VERSION ""

NS_ :

BS_:

BU_: BMS MC PDM D153 VCU

BO_ 165 INV_motorPositionInfo: 8 BMS
 SG_ INV_motorSpeed : 0|16@1- (0.1,0) [0|6500] ""  D153

BO_ 167 INV_voltageInfo: 8 MC
 SG_ INV_dcBusVoltage : 7|16@0- (1,0) [0|600] ""  D153

BO_ 170 INV_internalStates: 8 MC
 SG_ INV_limitCoolantDerating : 6|1@0- (1,-1) [-1|1] ""  D153
 SG_ INV_bmsTorqueLimiting : 7|1@0- (1,-1) [-1|1] ""  D153

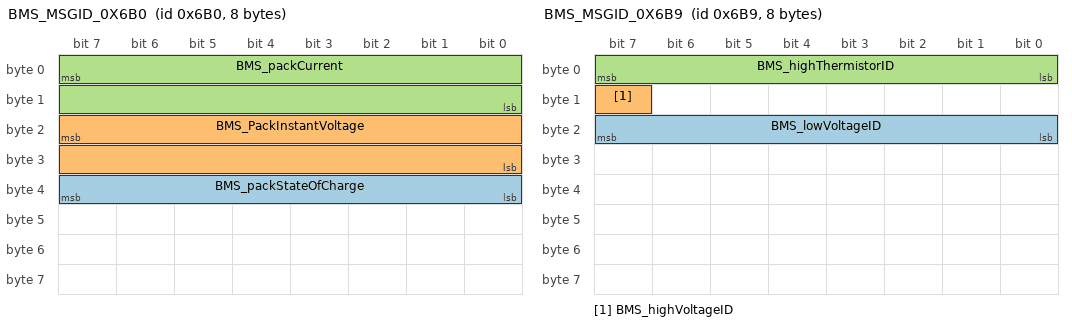
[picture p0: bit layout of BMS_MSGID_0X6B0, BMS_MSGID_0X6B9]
BO_ 1712 BMS_MSGID_0X6B0: 8 BMS
 SG_ BMS_packStateOfCharge : 39|8@0- (1,0) [0|100] ""  D153
 SG_ BMS_PackInstantVoltage : 23|16@0- (0.01,0) [0|600] "Volts"  D153
 SG_ BMS_packCurrent : 7|16@0- (0.01,0) [0|200] "Amps"  D153

BO_ 1714 BMS_MSGID_0X6B2: 8 BMS
 SG_ BMS_failsafeStatuses : 7|8@0- (1,0) [1|180] ""  D153

BO_ 54 BMS_MSGID_0X36_CELLBCAST: 8 BMS
 SG_ BMS_cellBalancing : 7|8@0- (1,0) [1|180] "bool"  D153

BO_ 1721 BMS_MSGID_0X6B9: 8 BMS
 SG_ BMS_lowVoltageID : 23|8@0- (1,0) [1|180] ""  D153
 SG_ BMS_highVoltageID : 15|1@0- (1,0) [1|180] ""  D153
 SG_ BMS_highThermistorID : 7|8@0- (1,0) [1|180] ""  D153

BO_ 1715 BMS_MSGID_0X6B3: 8 BMS
 SG_ BMS_lowThermistorID : 7|8@0- (1,0) [1|180] ""  D153

BO_ 1360 VCU_warning10Hz: 8 VCU
 SG_ VCU_mcCoolantFlowRateDiag m0 : 62|1@0- (1,0) [0|1] ""  D153
 SG_ VCU_gpsDiag m1 : 11|1@0- (1,0) [0|1] ""  D153
 SG_ VCU_CANBus3Diagnostic m1 : 13|1@0- (1,0) [0|1] ""  D153
 SG_ VCU_CANBus2Diagnostic m1 : 14|1@0- (1,0) [0|1] ""  D153
 SG_ VCU_CANBus1Diagnostic m1 : 15|1@0- (1,0) [0|1] ""  D153
 SG_ VCU_brakePressureSensorDiag m0 : 58|1@0- (1,0) [0|1] ""  D153
 SG_ VCU_warning10HzMux M : 7|8@0+ (1,0) [0|255] ""  D153
 SG_ VCU_tsOverPowerWarning m0 : 35|1@0- (1,0) [0|1] ""  D153
 SG_ VCU_throttlePedalSensorDiag m0 : 59|1@0- (1,0) [0|1] ""  D153
 SG_ VCU_rs232Diag m1 : 12|1@0- (1,0) [0|1] ""  D153
 SG_ VCU_radiatorCoolantFlowRateDiag m0 : 60|1@0- (1,0) [0|1] ""  D153
 SG_ VCU_radCoolantTempOutWarning m0 : 8|1@0- (1,0) [0|1] ""  D153
 SG_ VCU_radCoolantTempOutDiag m0 : 40|1@0- (1,0) [0|1] ""  D153
 SG_ VCU_radCoolantTempInWarning m0 : 9|1@0- (1,0) [0|1] ""  D153
 SG_ VCU_radCoolantTempInDiag m0 : 41|1@0- (1,0) [0|1] ""  D153
 SG_ VCU_radCoolantPressOutWarning m0 : 16|1@0- (1,0) [0|1] ""  D153
 SG_ VCU_radCoolantPressOutDiag m0 : 48|1@0- (1,0) [0|1] ""  D153
 SG_ VCU_radCoolantPressInWarning m0 : 17|1@0- (1,0) [0|1] ""  D153
 SG_ VCU_radCoolantPressInDiag m0 : 49|1@0- (1,0) [0|1] ""  D153
 SG_ VCU_radCoolantFlowRateWarning m0 : 28|1@0- (1,0) [0|1] ""  D153
 SG_ VCU_pedalPlausFaultWarning m0 : 33|1@0- (1,0) [0|1] ""  D153
 SG_ VCU_motorTorqueLimitWarning m1 : 21|1@0- (1,0) [0|1] ""  D153
 SG_ VCU_motorSpeedLimitWarning m1 : 22|1@0- (1,0) [0|1] ""  D153
 SG_ VCU_motorOverVoltWarning m0 : 26|1@0- (1,0) [0|1] ""  D153
 SG_ VCU_motorOverSpeedWarning m0 : 27|1@0- (1,0) [0|1] ""  D153
 SG_ VCU_motorOverCurrentWarning m0 : 25|1@0- (1,0) [0|1] ""  D153
 SG_ VCU_motorCoolantTempOutWarning m0 : 14|1@0- (1,0) [0|1] ""  D153
 SG_ VCU_motorCoolantTempOutDiag m0 : 46|1@0- (1,0) [0|1] ""  D153
 SG_ VCU_motorCoolantTempInWarning m0 : 15|1@0- (1,0) [0|1] ""  D153
 SG_ VCU_motorCoolantTempInDiag m0 : 47|1@0- (1,0) [0|1] ""  D153
 SG_ VCU_motorCoolantPressOutWarning m0 : 22|1@0- (1,0) [0|1] ""  D153
 SG_ VCU_motorCoolantPressOutDiag m0 : 49|1@1- (1,0) [0|1] ""  D153
 SG_ VCU_motorCoolantPressInWarning m0 : 23|1@0- (1,0) [0|1] ""  D153
 SG_ VCU_motorCoolantPressInDiag m0 : 55|1@0- (1,0) [0|1] ""  D153
 SG_ VCU_motorCoolantFlowRateWarning m0 : 31|1@0- (1,0) [0|1] ""  D153
 SG_ VCU_motorCoolantFlowRateDiag m0 : 63|1@0- (1,0) [0|1] ""  D153
 SG_ VCU_mcOverVoltWarning m0 : 24|1@0- (1,0) [0|1] ""  D153
 SG_ VCU_mcOverCurrentWarning m0 : 39|1@0- (1,0) [0|1] ""  D153
 SG_ VCU_mcCoolantTempOutWarning m0 : 12|1@0- (1,0) [0|1] ""  D153
 SG_ VCU_mcCoolantTempOutDiag m0 : 44|1@0- (1,0) [0|1] ""  D153
 SG_ VCU_mcCoolantTempInWarning m0 : 13|1@0- (1,0) [0|1] ""  D153
 SG_ VCU_mcCoolantTempInDiag m0 : 45|1@0- (1,0) [0|1] ""  D153
 SG_ VCU_mcCoolantPressOutWarning : 20|1@0- (1,0) [0|1] ""  D153
 SG_ VCU_mcCoolantPressOutDiag m0 : 52|1@0- (1,0) [0|1] ""  D153
 SG_ VCU_mcCoolantPressInWarning m0 : 21|1@0- (1,0) [0|1] ""  D153
 SG_ VCU_mcCoolantPressInDiag m0 : 53|1@0- (1,0) [0|1] ""  D153
 SG_ VCU_mcCoolantFlowRateWarning m0 : 30|1@0- (1,0) [0|1] ""  D153
 SG_ VCU_mcCANTimeoutWarning m1 : 10|1@0- (1,0) [0|1] ""  D153
 SG_ VCU_batteryUnderVoltWarning m0 : 34|1@0- (1,0) [0|1] ""  D153
 SG_ VCU_accuUnderVoltWarning m0 : 37|1@0- (1,0) [0|1] ""  D153
 SG_ VCU_accuOverVoltWarning m0 : 38|1@0- (1,0) [0|1] ""  D153
 SG_ VCU_accuOverCurrentWarning m0 : 36|1@0- (1,0) [0|1] ""  D153
 SG_ VCU_accumulatorTempWarning m0 : 32|1@0- (1,0) [0|1] ""  D153
 SG_ VCU_accuIMDLightWarning m1 : 8|1@0- (1,0) [0|1] ""  D153
 SG_ VCU_accuHVILWarning m1 : 23|1@0- (1,0) [0|1] ""  D153
 SG_ VCU_accuCoolantTempOutWarning m0 : 10|1@0- (1,0) [0|1] ""  D153
 SG_ VCU_accuCoolantTempOutDiag m0 : 42|1@0- (1,0) [0|1] ""  D153
 SG_ VCU_accuCoolantTempInWarning m0 : 11|1@0- (1,0) [0|1] ""  D153
 SG_ VCU_accuCoolantTempInDiag m0 : 43|1@0- (1,0) [0|1] ""  D153
 SG_ VCU_accuCoolantPressOutWarning m0 : 18|1@0- (1,0) [0|1] ""  D153
 SG_ VCU_accuCoolantPressOutDiag m0 : 50|1@0- (1,0) [0|1] ""  D153
 SG_ VCU_accuCoolantPressInWarning m0 : 19|1@0- (1,0) [0|1] ""  D153
 SG_ VCU_accuCoolantPressInDiag m0 : 51|1@0- (1,0) [0|1] ""  D153
 SG_ VCU_accuCoolantFlowRateWarning m0 : 29|1@0- (1,0) [0|1] ""  D153
 SG_ VCU_accuCoolantFlowRateDiag m0 : 61|1@0- (1,0) [0|1] ""  D153
 SG_ VCU_accuCANTimeoutWarning m1 : 9|1@0- (1,0) [0|1] ""  D153

BO_ 1104 PDM_pdmCurrentTotal: 8 PDM
 SG_ PDM_pdmTotalCurrent : 7|8@0- (1,0) [0|100] "Amps"  D153

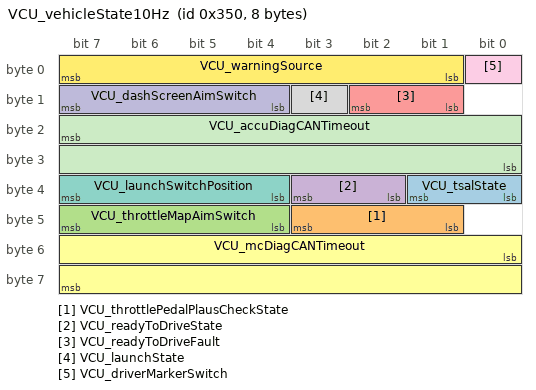
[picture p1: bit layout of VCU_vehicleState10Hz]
BO_ 848 VCU_vehicleState10Hz: 8 VCU
 SG_ VCU_tsalState : 33|2@0- (1,0) [0|3] ""  D153
 SG_ VCU_throttlePedalPlausCheckState : 43|3@0- (1,-4) [-4|4] ""  D153
 SG_ VCU_throttleMapAimSwitch : 47|4@0- (1,-1) [-1|9] ""  D153
 SG_ VCU_readyToDriveState : 35|2@0- (1,-2) [-2|2] ""  D153
 SG_ VCU_readyToDriveFault : 10|2@0- (1,-3) [-3|3] ""  D153
 SG_ VCU_mcDiagCANTimeout : 48|16@1- (1,0) [0|10000] "ms"  D153
 SG_ VCU_launchSwitchPosition : 39|4@0- (1,-9) [-9|9] ""  D153
 SG_ VCU_launchState : 11|1@0- (1,0) [0|1] ""  D153
 SG_ VCU_driverMarkerSwitch : 0|1@0- (1,0) [0|1] ""  D153
 SG_ VCU_dashScreenAimSwitch : 15|4@0- (1,-9) [-9|9] ""  D153
 SG_ VCU_accuDiagCANTimeout : 23|16@0- (1,0) [0|10000] "ms"  D153
 SG_ VCU_warningSource : 7|7@0- (1,0) [0|65] ""  D153

BO_ 592 VCU_vehicleInfo10Hz: 8 VCU
 SG_ VCU_vechicleInfo10HzMux M : 7|8@0+ (1,0) [0|255] ""  D153
 SG_ VCU_yawRate m3 : 47|16@0- (0.01,-100) [-100|100] "deg/s"  D153
 SG_ VCU_verticalAcceleration m2 : 47|16@0- (0.001,-5) [-5|5] "G"  D153
 SG_ VCU_vehicleSpeed m0 : 15|16@0- (0.01,0) [0|300] "km/h"  D153
 SG_ VCU_vcuBatteryVoltage m1 : 31|8@0- (1,0) [0|28] "Volts"  D153
 SG_ VCU_throttlePedalTorqueMap m0 : 31|16@0- (0.1,-500) [-500|500] "Newton-Meter"  D153
 SG_ VCU_rollRate m3 : 31|16@0- (0.01,-100) [-100|100] "deg/s"  D153
 SG_ VCU_pitchRate m3 : 15|16@0- (0.01,-100) [-100|100] "deg/s"  D153
 SG_ VCU_longitudinalAcceleration m2 : 31|16@0- (0.001,-5) [-5|5] "G"  D153
 SG_ VCU_lateralAcceleration m2 : 15|16@0- (0.001,-5) [-5|5] "G"  D153
 SG_ VCU_brakeBiasAim m0 : 47|8@0- (1,0) [0|100] "Percent"  D153
 SG_ VCU_accumEstimatedPower m1 : 15|16@0- (1,0) [0|1200] "Watt"  D153

BO_ 1616 VCU_componentTemp10Hz: 8 VCU
 SG_ VCU_motorTemp m0 : 15|16@0- (0.1,-3276) [-3276|3276] "Celcius"  D153
 SG_ VCU_mcTempHotSpot m0 : 47|16@0- (1,-3276) [-3276|3276] "Celcius"  D153
 SG_ VCU_mcTempCoolant m0 : 31|16@0- (0.1,-3276) [-3276|3276] "Celcius"  D153
 SG_ VCU_accuLowestTemp m2 : 31|16@0- (0.1,-3276) [-3276|3276] "Celcius"  D153
 SG_ VCU_accuInternalTemp m1 : 15|16@0- (0.1,-3276) [-3276|3276] "Celcius"  D153
 SG_ VCU_accuHighestTemp m2 : 15|16@0- (0.1,-3276) [-3276|3276] "Celcius"  D153
 SG_ VCU_accuAverageTemp m1 : 31|16@0- (0.1,-3276) [-3276|3276] "Celcius"  D153
 SG_ VCU_componentTemp10HzMux M : 7|8@0+ (1,0) [0|255] ""  D153

BO_ 1872 VCU_tireInfo10Hz: 8 VCU
 SG_ VCU_tireInfo10HzMux M : 7|8@0+ (1,0) [0|255] ""  D153
 SG_ VCU_avgTireTempRR m1 : 31|16@0- (0.1,0) [0|100] "Celcius"  D153
 SG_ VCU_avgTireTempRL m1 : 15|16@0- (0.1,0) [0|100] "Celcius"  D153
 SG_ VCU_avgTireTempFR m0 : 31|16@0- (0.1,0) [0|100] "Celcius"  D153
 SG_ VCU_avgTireTempFL m0 : 15|16@0- (0.1,0) [0|100] "Celcius"  D153

BO_ 1600 VCU_coolantInfo10Hz: 8 VCU
 SG_ VCU_radCoolantTempOut m3 : 55|8@0- (1,-250) [-250|250] "Celcius"  D153
 SG_ VCU_radCoolantTempIn m3 : 47|8@0- (1,-250) [-250|250] "Celcius"  D153
 SG_ VCU_radCoolantPressOut m3 : 31|16@0- (0.1,0) [0|300] "kPa"  D153
 SG_ VCU_radCoolantPressIn m3 : 15|16@0- (0.1,0) [0|300] "kPa"  D153
 SG_ VCU_motorCoolantTempOut m1 : 55|8@0- (1,-250) [-250|250] "Celcius"  D153
 SG_ VCU_motorCoolantTempIn m1 : 47|8@0- (1,-250) [-250|250] "Celcius"  D153
 SG_ VCU_motorCoolantPressOut m1 : 31|16@0- (0.1,0) [0|300] "kPa"  D153
 SG_ VCU_motorCoolantPressIn m1 : 15|16@0- (0.1,0) [0|300] "kPa"  D153
 SG_ VCU_motorCoolantFlowRate m4 : 15|16@0- (0.1,0) [0|100] "L/min"  D153
 SG_ VCU_mcCoolantTempOut m2 : 55|8@0- (1,-250) [-250|250] "Celcius"  D153
 SG_ VCU_mcCoolantTempIn m2 : 47|8@0- (1,-250) [-250|250] "Celcius"  D153
 SG_ VCU_mcCoolantPressOut m2 : 31|16@0- (0.1,0) [0|300] "kPa"  D153
 SG_ VCU_mcCoolantPressIn m2 : 15|16@0- (0.1,0) [0|300] "kPa"  D153
 SG_ VCU_mcCoolantFlowRate m4 : 31|16@0- (0.1,0) [0|100] "L/min"  D153
 SG_ VCU_accuCoolantTempOut m0 : 55|8@0- (1,-250) [-250|250] "Celcius "  D153
 SG_ VCU_accuCoolantTempIn m0 : 47|8@0- (1,-250) [-250|250] "Celcius"  D153
 SG_ VCU_accuCoolantPressOut m0 : 31|16@0- (0.1,0) [0|300] "kPa"  D153
 SG_ VCU_coolantInfo10HzMux M : 7|8@0+ (1,0) [0|255] ""  D153
 SG_ VCU_accuCoolantPressIn m0 : 15|16@0- (0.1,0) [0|300] "kPa"  D153

BA_DEF_  "BusType" STRING ;
BA_DEF_DEF_  "BusType" "CAN";
